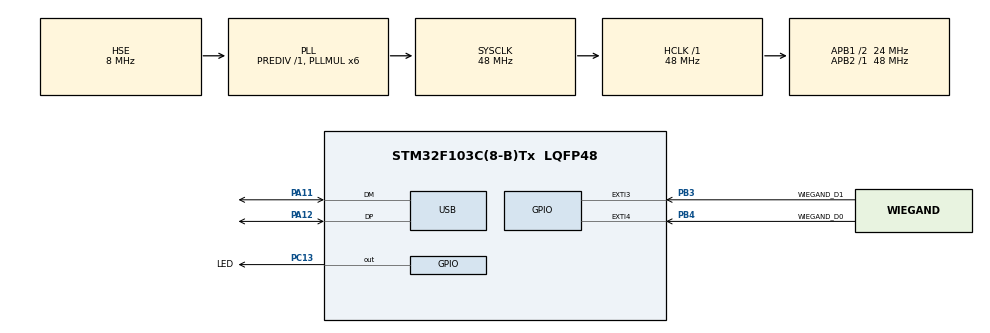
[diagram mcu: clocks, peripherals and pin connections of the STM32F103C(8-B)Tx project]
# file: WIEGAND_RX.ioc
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Mcu.Family=STM32F1
NVIC.EXTI4_IRQn=true\:0\:0\:false\:false\:true\:true\:true
USB_DEVICE.CLASS_NAME_FS=CDC
PD1-OSC_OUT.Mode=HSE-External-Oscillator
USB_DEVICE.VirtualModeFS=Cdc_FS
PB4.GPIO_ModeDefaultEXTI=GPIO_MODE_IT_FALLING
NVIC.EXTI3_IRQn=true\:0\:0\:false\:false\:true\:true\:true
PC13-TAMPER-RTC.Signal=GPIO_Output
PA11.Mode=Device
NVIC.TIM1_UP_IRQn=true\:0\:0\:false\:false\:true\:true\:true
PB3.GPIO_ModeDefaultEXTI=GPIO_MODE_IT_FALLING
PD0-OSC_IN.Signal=RCC_OSC_IN
RCC.APB1CLKDivider=RCC_HCLK_DIV2
RCC.SYSCLKSource=RCC_SYSCLKSOURCE_PLLCLK
ProjectManager.StackSize=0x400
PD1-OSC_OUT.Signal=RCC_OSC_OUT
PA13.Signal=SYS_JTMS-SWDIO
PA12.Signal=USB_DP
TIM1.Prescaler=4700
ProjectManager.TargetToolchain=STM32CubeIDE
RCC.HCLKFreq_Value=48000000
VP_USB_DEVICE_VS_USB_DEVICE_CDC_FS.Mode=CDC_FS
RCC.APB2TimFreq_Value=48000000
PB4.GPIO_PuPd=GPIO_NOPULL
RCC.USBFreq_Value=48000000
RCC.AHBFreq_Value=48000000
PD0-OSC_IN.Mode=HSE-External-Oscillator
board=custom
PC13-TAMPER-RTC.GPIO_Label=LED
RCC.PLLMUL=RCC_PLL_MUL6
RCC.APB2Freq_Value=48000000
PB3.GPIO_PuPd=GPIO_NOPULL
PB4.GPIO_Label=WIEGAND_D0
PA14.Mode=Serial_Wire
NVIC.USB_LP_CAN1_RX0_IRQn=true\:0\:0\:false\:false\:true\:false\:true
PA13.Mode=Serial_Wire
Mcu.Name=STM32F103C(8-B)Tx
VP_TIM1_VS_ClockSourceINT.Mode=Internal
PB3.Signal=GPXTI3
RCC.SYSCLKFreq_VALUE=48000000
Mcu.Package=LQFP48
PA12.Mode=Device
PA11.Signal=USB_DM
PA14.Signal=SYS_JTCK-SWCLK
ProjectManager.HeapSize=0x200
NVIC.PriorityGroup=NVIC_PRIORITYGROUP_4
RCC.APB1TimFreq_Value=48000000
RCC.APB1Freq_Value=24000000
USB_DEVICE.VirtualMode=Cdc
PB4.Signal=GPXTI4
PB3.GPIO_Label=WIEGAND_D1

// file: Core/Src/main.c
/* USER CODE BEGIN Header */
/**
  ******************************************************************************
  * @file           : main.c
  * @brief          : Main program body
  ******************************************************************************
  * @attention
  *
  * <h2><center>&copy; Copyright (c) 2021 STMicroelectronics.
  * All rights reserved.</center></h2>
  *
  * This software component is licensed by ST under BSD 3-Clause license,
  * the "License"; You may not use this file except in compliance with the
  * License. You may obtain a copy of the License at:
  *                        opensource.org/licenses/BSD-3-Clause
  *
  ******************************************************************************
  */
/* USER CODE END Header */
#include "main.h"
#include "usb_device.h"

/* USER CODE BEGIN Includes */
#include "wiegand.h"
/* USER CODE END Includes */

TIM_HandleTypeDef htim1;

void SystemClock_Config(void);
static void MX_GPIO_Init(void);
static void MX_TIM1_Init(void);

/* USER CODE BEGIN 0 */
extern void initialise_monitor_handles(void);
/* USER CODE END 0 */

int main(void)
{
  /* USER CODE BEGIN 1 */
	initialise_monitor_handles();
	printf("Start\n");
	WiegandInit(&htim1);
  /* USER CODE END 1 */

  /* MCU Configuration--------------------------------------------------------*/

  /* Reset of all peripherals, Initializes the Flash interface and the Systick. */
  HAL_Init();

  /* Configure the system clock */
  SystemClock_Config();

  /* Initialize all configured peripherals */
  MX_GPIO_Init();
  MX_TIM1_Init();
  MX_USB_DEVICE_Init();
  /* USER CODE BEGIN 2 */
  WiegandInit(&htim1);
  /* USER CODE END 2 */

  /* Infinite loop */
  while (1)
  {

  }
}

void SystemClock_Config(void)
{
  RCC_OscInitTypeDef RCC_OscInitStruct = {0};
  RCC_ClkInitTypeDef RCC_ClkInitStruct = {0};
  RCC_PeriphCLKInitTypeDef PeriphClkInit = {0};

  /** Initializes the RCC Oscillators according to the specified parameters
  * in the RCC_OscInitTypeDef structure.
  */
  RCC_OscInitStruct.OscillatorType = RCC_OSCILLATORTYPE_HSE;
  RCC_OscInitStruct.HSEState = RCC_HSE_ON;
  RCC_OscInitStruct.HSEPredivValue = RCC_HSE_PREDIV_DIV1;
  RCC_OscInitStruct.HSIState = RCC_HSI_ON;
  RCC_OscInitStruct.PLL.PLLState = RCC_PLL_ON;
  RCC_OscInitStruct.PLL.PLLSource = RCC_PLLSOURCE_HSE;
  RCC_OscInitStruct.PLL.PLLMUL = RCC_PLL_MUL6;
  if (HAL_RCC_OscConfig(&RCC_OscInitStruct) != HAL_OK)
  {
    Error_Handler();
  }
  /** Initializes the CPU, AHB and APB buses clocks
  */
  RCC_ClkInitStruct.ClockType = RCC_CLOCKTYPE_HCLK|RCC_CLOCKTYPE_SYSCLK
                              |RCC_CLOCKTYPE_PCLK1|RCC_CLOCKTYPE_PCLK2;
  RCC_ClkInitStruct.SYSCLKSource = RCC_SYSCLKSOURCE_PLLCLK;
  RCC_ClkInitStruct.AHBCLKDivider = RCC_SYSCLK_DIV1;
  RCC_ClkInitStruct.APB1CLKDivider = RCC_HCLK_DIV2;
  RCC_ClkInitStruct.APB2CLKDivider = RCC_HCLK_DIV1;

  if (HAL_RCC_ClockConfig(&RCC_ClkInitStruct, FLASH_LATENCY_1) != HAL_OK)
  {
    Error_Handler();
  }
  PeriphClkInit.PeriphClockSelection = RCC_PERIPHCLK_USB;
  PeriphClkInit.UsbClockSelection = RCC_USBCLKSOURCE_PLL;
  if (HAL_RCCEx_PeriphCLKConfig(&PeriphClkInit) != HAL_OK)
  {
    Error_Handler();
  }
}

static void MX_TIM1_Init(void)
{

  TIM_ClockConfigTypeDef sClockSourceConfig = {0};
  TIM_MasterConfigTypeDef sMasterConfig = {0};

  htim1.Instance = TIM1;
  htim1.Init.Prescaler = 4700;
  htim1.Init.CounterMode = TIM_COUNTERMODE_UP;
  htim1.Init.Period = 65535;
  htim1.Init.ClockDivision = TIM_CLOCKDIVISION_DIV1;
  htim1.Init.RepetitionCounter = 0;
  htim1.Init.AutoReloadPreload = TIM_AUTORELOAD_PRELOAD_DISABLE;
  if (HAL_TIM_Base_Init(&htim1) != HAL_OK)
  {
    Error_Handler();
  }
  sClockSourceConfig.ClockSource = TIM_CLOCKSOURCE_INTERNAL;
  if (HAL_TIM_ConfigClockSource(&htim1, &sClockSourceConfig) != HAL_OK)
  {
    Error_Handler();
  }
  sMasterConfig.MasterOutputTrigger = TIM_TRGO_RESET;
  sMasterConfig.MasterSlaveMode = TIM_MASTERSLAVEMODE_DISABLE;
  if (HAL_TIMEx_MasterConfigSynchronization(&htim1, &sMasterConfig) != HAL_OK)
  {
    Error_Handler();
  }

}

static void MX_GPIO_Init(void)
{
  GPIO_InitTypeDef GPIO_InitStruct = {0};

  /* GPIO Ports Clock Enable */
  __HAL_RCC_GPIOC_CLK_ENABLE();
  __HAL_RCC_GPIOD_CLK_ENABLE();
  __HAL_RCC_GPIOA_CLK_ENABLE();
  __HAL_RCC_GPIOB_CLK_ENABLE();

  /*Configure GPIO pin Output Level */
  HAL_GPIO_WritePin(LED_GPIO_Port, LED_Pin, GPIO_PIN_RESET);

  /*Configure GPIO pin : LED_Pin */
  GPIO_InitStruct.Pin = LED_Pin;
  GPIO_InitStruct.Mode = GPIO_MODE_OUTPUT_PP;
  GPIO_InitStruct.Pull = GPIO_NOPULL;
  GPIO_InitStruct.Speed = GPIO_SPEED_FREQ_LOW;
  HAL_GPIO_Init(LED_GPIO_Port, &GPIO_InitStruct);

  /*Configure GPIO pins : WIEGAND_D1_Pin WIEGAND_D0_Pin */
  GPIO_InitStruct.Pin = WIEGAND_D1_Pin|WIEGAND_D0_Pin;
  GPIO_InitStruct.Mode = GPIO_MODE_IT_FALLING;
  GPIO_InitStruct.Pull = GPIO_NOPULL;
  HAL_GPIO_Init(GPIOB, &GPIO_InitStruct);

  /* EXTI interrupt init*/
  HAL_NVIC_SetPriority(EXTI3_IRQn, 0, 0);
  HAL_NVIC_EnableIRQ(EXTI3_IRQn);

  HAL_NVIC_SetPriority(EXTI4_IRQn, 0, 0);
  HAL_NVIC_EnableIRQ(EXTI4_IRQn);

}

void Error_Handler(void)
{
  __disable_irq();
  while (1)
  {
  }
}

/************************ (C) COPYRIGHT STMicroelectronics *****END OF FILE****/
